# STM32MP157 register map
File version: 1.7
CPU: CM4 r0p1, little endian, no MPU, FPU, 4 interrupt priority bits
Registers are 32-bit, read-write, reset 0x0 unless marked. A register's access mark holds for its fields unless they carry their own. Offsets are from the block's base; [hi:lo] are bit positions.

## I2C1
Base 0x40012000
Same registers: I2C2 0x40013000, I2C3 0x40014000, I2C5 0x40015000, I2C4 0x5C002000, I2C6 0x5C009000
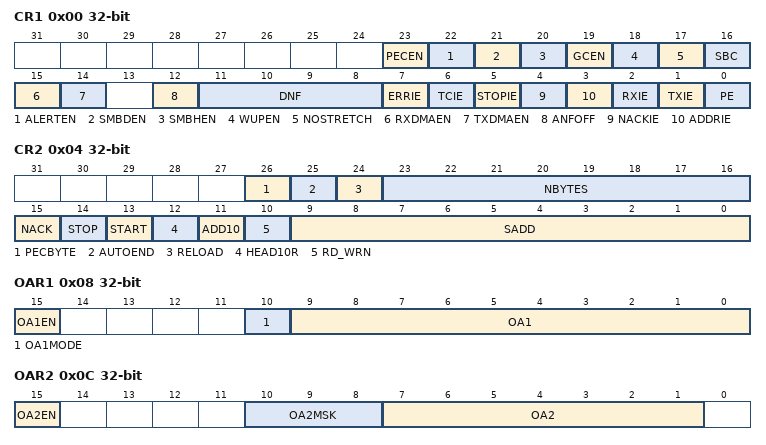
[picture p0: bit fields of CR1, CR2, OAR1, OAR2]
0x00 CR1 — Access: No wait states, except if a write access occurs while a write access to this register is ongoing. In this case, wait states are inserted in the second write access until the previous one is completed. The latency of the second write access can be up to 2xi2c_pclk+6xi2c_ker_ck.
  [23] PECEN, [22] ALERTEN, [21] SMBDEN, [20] SMBHEN, [19] GCEN, [18] WUPEN, [17] NOSTRETCH, [16] SBC, [15] RXDMAEN, [14] TXDMAEN, [12] ANFOFF, [11:8] DNF, [7] ERRIE, [6] TCIE, [5] STOPIE, [4] NACKIE, [3] ADDRIE, [2] RXIE, [1] TXIE, [0] PE
0x04 CR2 — Access: No wait states, except if a write access occurs while a write access to this register is ongoing. In this case, wait states are inserted in the second write access until the previous one is completed. The latency of the second write access can be up to 2 x i2c_pclk + 6 x i2c_ker_ck.
  [26] PECBYTE, [25] AUTOEND, [24] RELOAD, [23:16] NBYTES, [15] NACK, [14] STOP, [13] START, [12] HEAD10R, [11] ADD10, [10] RD_WRN, [9:0] SADD
0x08 OAR1 — Access: No wait states, except if a write access occurs while a write access to this register is ongoing. In this case, wait states are inserted in the second write access until the previous one is completed. The latency of the second write access can be up to 2 x i2c_pclk + 6 x i2c_ker_ck.
  [15] OA1EN, [10] OA1MODE, [9:0] OA1
0x0C OAR2 — Access: No wait states, except if a write access occurs while a write access to this register is ongoing. In this case, wait states are inserted in the second write access until the previous one is completed. The latency of the second write access can be up to 2 x i2c_pclk + 6 x i2c_ker_ck.
  [15] OA2EN, [10:8] OA2MSK, [7:1] OA2
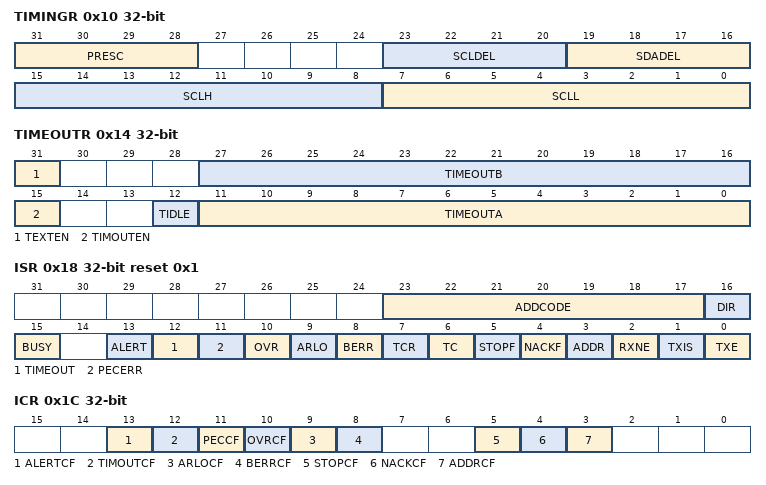
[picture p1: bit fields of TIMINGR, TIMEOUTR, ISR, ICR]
0x10 TIMINGR — Access: No wait states
  [31:28] PRESC, [23:20] SCLDEL, [19:16] SDADEL, [15:8] SCLH, [7:0] SCLL
0x14 TIMEOUTR — Access: No wait states, except if a write access occurs while a write access to this register is ongoing. In this case, wait states are inserted in the second write access until the previous one is completed. The latency of the second write access can be up to 2 x i2c_pclk + 6 x i2c_ker_ck.
  [31] TEXTEN, [27:16] TIMEOUTB, [15] TIMOUTEN, [12] TIDLE, [11:0] TIMEOUTA
0x18 ISR access per field reset 0x1 — Access: No wait states
  [23:17] ADDCODE ro, [16] DIR ro, [15] BUSY ro, [13] ALERT ro, [12] TIMEOUT ro, [11] PECERR ro, [10] OVR ro, [9] ARLO ro, [8] BERR ro, [7] TCR ro, [6] TC ro, [5] STOPF ro, [4] NACKF ro, [3] ADDR ro, [2] RXNE ro, [1] TXIS rw, [0] TXE rw
0x1C ICR wo — Access: No wait states
  [13] ALERTCF, [12] TIMOUTCF, [11] PECCF, [10] OVRCF, [9] ARLOCF, [8] BERRCF, [5] STOPCF, [4] NACKCF, [3] ADDRCF
0x20 PECR ro — Access: No wait states
  [7:0] PEC
0x24 RXDR ro — Access: No wait states
  [7:0] RXDATA
0x28 TXDR — Access: No wait states
  [7:0] TXDATA
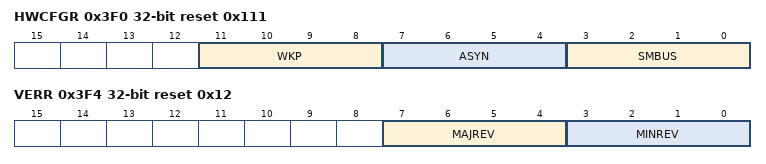
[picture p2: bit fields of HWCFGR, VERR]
0x3F0 HWCFGR ro reset 0x111 — I2C hardware configuration register
  [11:8] WKP, [7:4] ASYN, [3:0] SMBUS
0x3F4 VERR ro reset 0x12 — I2C version register
  [7:4] MAJREV, [3:0] MINREV
0x3F8 IPIDR ro reset 0x130012 — I2C identification register
  [31:0] ID
0x3FC SIDR ro reset 0xA3C5DD01 — I2C size identification register
  [31:0] SID

## IPCC
Base 0x4C001000
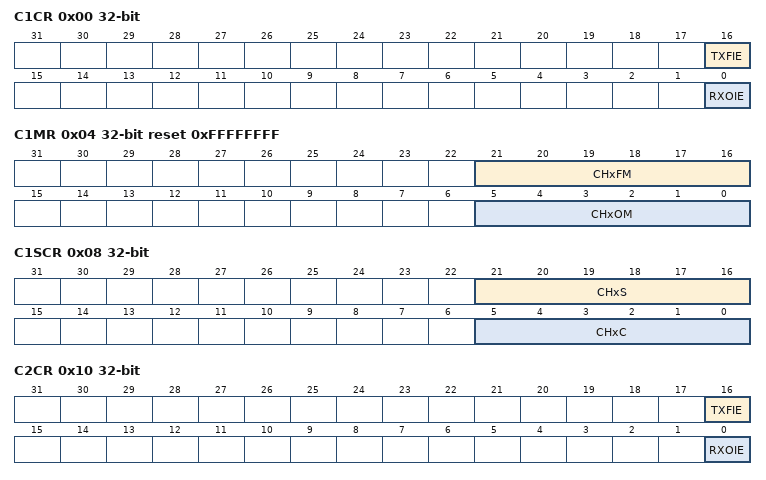
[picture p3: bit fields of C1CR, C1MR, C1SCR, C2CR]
0x00 C1CR — IPCC Processor 1 control register
  [16] TXFIE, [0] RXOIE
0x04 C1MR reset 0xFFFFFFFF — IPCC Processor 1 mask register
  [21:16] CHxFM, [5:0] CHxOM
0x08 C1SCR — Reading this register will always return 0x0000 0000.
  [21:16] CHxS, [5:0] CHxC
0x0C C1TOC2SR ro — IPCC processor 1 to processor 2 status register
  [5:0] CHxF
0x10 C2CR — IPCC Processor 2 control register
  [16] TXFIE, [0] RXOIE
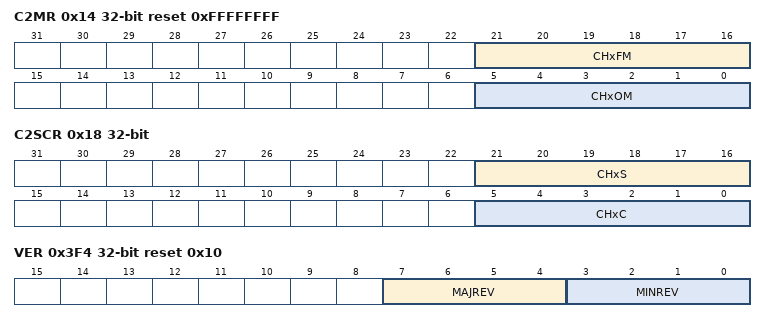
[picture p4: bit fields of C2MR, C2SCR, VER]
0x14 C2MR reset 0xFFFFFFFF — IPCC Processor 2 mask register
  [21:16] CHxFM, [5:0] CHxOM
0x18 C2SCR — Reading this register will always return 0x0000 0000.
  [21:16] CHxS, [5:0] CHxC
0x1C C2TOC1SR ro — IPCC processor 2 to processor 1 status register
  [5:0] CHxF
0x3F0 HWCFGR ro reset 0x2 — IPCC Hardware configuration register
  [7:0] CHANNELS
0x3F4 VER ro reset 0x10 — IPCC IP Version register
  [7:4] MAJREV, [3:0] MINREV
0x3F8 ID ro reset 0x100071 — IPCC IP Identification register
  [31:0] IPID
0x3FC SID ro reset 0xA3C5DD01 — IPCC Size ID register
